# MSP430F5529 register map
Vendor: msp430gen; File version: v0.4.0-10-gd4db4bc
Registers are 8-bit, read-write, reset 0x0 unless marked. A register's access mark holds for its fields unless they carry their own. Offsets are from the block's base; [hi:lo] are bit positions; {n}, {i} and the like mark numbered series.

## USCI_A1_UART_MODE
Base 0x00000600
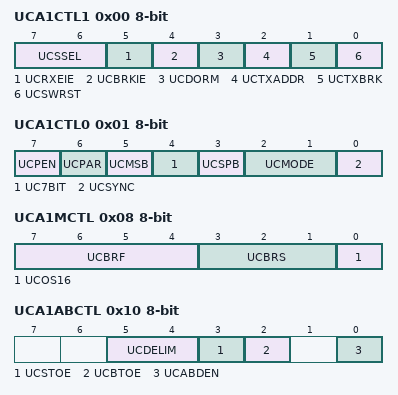
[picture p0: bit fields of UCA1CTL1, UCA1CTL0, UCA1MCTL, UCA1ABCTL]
0x00 UCA1CTL1 — USCI A1 Control Register 1
  [7:6] UCSSEL — USCI 0 Clock Source Select 1
    {v}=USCI 0 Clock Source: {v} (v=0..3)
  [5] UCRXEIE — RX Error interrupt enable
  [4] UCBRKIE — Break interrupt enable
  [3] UCDORM — Dormant (Sleep) Mode
  [2] UCTXADDR — Send next Data as Address
  [1] UCTXBRK — Send next Data as Break
  [0] UCSWRST — USCI Software Reset
0x01 UCA1CTL0 — USCI A1 Control Register 0
  [7] UCPEN — Async. Mode: Parity enable
  [6] UCPAR — Async. Mode: Parity 0:odd / 1:even
  [5] UCMSB — Async. Mode: MSB first 0:LSB / 1:MSB
  [4] UC7BIT — Async. Mode: Data Bits 0:8-bits / 1:7-bits
  [3] UCSPB — Async. Mode: Stop Bits 0:one / 1: two
  [2:1] UCMODE — Async. Mode: USCI Mode 1
    {v}=Sync. Mode: USCI Mode: {v} (v=0..3)
  [0] UCSYNC — Sync-Mode 0:UART-Mode / 1:SPI-Mode
0x06 UCA1BR0 — USCI A1 Baud Rate 0
  [7:0] UCA1BR0 — USCI A1 Baud Rate 0 register
0x07 UCA1BR1 — USCI A1 Baud Rate 1
  [7:0] UCA1BR1 — USCI A1 Baud Rate 1 register
0x08 UCA1MCTL — USCI A1 Modulation Control
  [7:4] UCBRF — USCI First Stage Modulation Select 3
    {v}=USCI First Stage Modulation: {v} (v=0..9); 10=USCI First Stage Modulation: A; 11=USCI First Stage Modulation: B; 12=USCI First Stage Modulation: C; 13=USCI First Stage Modulation: D; 14=USCI First Stage Modulation: E; 15=USCI First Stage Modulation: F
  [3:1] UCBRS — USCI Second Stage Modulation Select 2
    {v}=USCI Second Stage Modulation: {v} (v=0..7)
  [0] UCOS16 — USCI 16-times Oversampling enable
0x0A UCA1STAT — USCI A1 Status Register
  [7] UCLISTEN — USCI Listen mode
  [6] UCFE — USCI Frame Error Flag
  [5] UCOE — USCI Overrun Error Flag
  [4] UCPE — USCI Parity Error Flag
  [3] UCBRK — USCI Break received
  [2] UCRXERR — USCI RX Error Flag
  [1] UCADDR — USCI Address received Flag
  [1] UCIDLE — Idle line detected
  [0] UCBUSY — USCI Busy Flag
0x0C UCA1RXBUF — USCI A1 Receive Buffer
  [7:0] UCA1RXBUF — USCI A1 Receive Buffer register
0x0E UCA1TXBUF — USCI A1 Transmit Buffer
  [7:0] UCA1TXBUF — USCI A1 Transmit Buffer register
0x10 UCA1ABCTL — USCI A1 LIN Control
  [5:4] UCDELIM — Break Sync Delimiter 0
  [3] UCSTOE — Sync-Field Timeout error
  [2] UCBTOE — Break Timeout error
  [0] UCABDEN — Auto Baud Rate detect enable
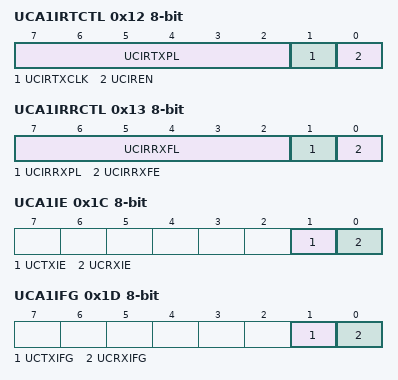
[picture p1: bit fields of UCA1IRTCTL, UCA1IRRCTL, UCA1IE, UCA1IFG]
0x12 UCA1IRTCTL — USCI A1 IrDA Transmit Control
  [7:2] UCIRTXPL — IRDA Transmit Pulse Length 0
  [1] UCIRTXCLK — IRDA Transmit Pulse Clock Select
  [0] UCIREN — IRDA Encoder/Decoder enable
0x13 UCA1IRRCTL — USCI A1 IrDA Receive Control
  [7:2] UCIRRXFL — IRDA Receive Filter Length 0
  [1] UCIRRXPL — IRDA Receive Input Polarity
  [0] UCIRRXFE — IRDA Receive Filter enable
0x1C UCA1IE — USCI A1 Interrupt Enable Register
  [1] UCTXIE — USCI Transmit Interrupt Enable
  [0] UCRXIE — USCI Receive Interrupt Enable
0x1D UCA1IFG — USCI A1 Interrupt Flags Register
  [1] UCTXIFG — USCI Transmit Interrupt Flag
  [0] UCRXIFG — USCI Receive Interrupt Flag
0x1E UCA1IV 16-bit — USCI A1 Interrupt Vector Register

## USCI_A1_SPI_MODE
Base 0x00000600
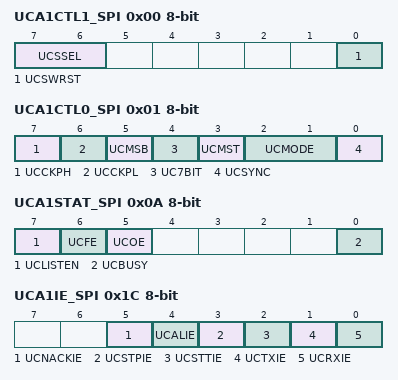
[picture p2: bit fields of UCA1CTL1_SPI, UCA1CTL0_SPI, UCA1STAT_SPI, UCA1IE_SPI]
0x00 UCA1CTL1_SPI — USCI A1 Control Register 1
  [7:6] UCSSEL — USCI 1 Clock Source Select 1
    {v}=USCI 0 Clock Source: {v} (v=0..3)
  [0] UCSWRST — USCI Software Reset
0x01 UCA1CTL0_SPI — USCI A1 Control Register 0
  [7] UCCKPH — Sync. Mode: Clock Phase
  [6] UCCKPL — Sync. Mode: Clock Polarity
  [5] UCMSB — Sync. Mode: MSB first 0:LSB / 1:MSB
  [4] UC7BIT — Sync. Mode: Data Bits 0:8-bits / 1:7-bits
  [3] UCMST — Sync. Mode: Master Select
  [2:1] UCMODE — Sync. Mode: USCI Mode 1
    {v}=Sync. Mode: USCI Mode: {v} (v=0..3)
  [0] UCSYNC — Sync-Mode 0:UART-Mode / 1:SPI-Mode
0x06 UCA1BR0_SPI — USCI A1 Baud Rate 0
0x07 UCA1BR1_SPI — USCI A1 Baud Rate 1
0x08 UCA1MCTL_SPI — USCI A1 Modulation Control
0x0A UCA1STAT_SPI — USCI A1 Status Register
  [7] UCLISTEN — USCI Listen mode
  [6] UCFE — USCI Frame Error Flag
  [5] UCOE — USCI Overrun Error Flag
  [0] UCBUSY — USCI Busy Flag
0x0C UCA1RXBUF_SPI — USCI A1 Receive Buffer
0x0E UCA1TXBUF_SPI — USCI A1 Transmit Buffer
0x1C UCA1IE_SPI — USCI A1 Interrupt Enable Register
  [5] UCNACKIE — NACK Condition interrupt enable
  [4] UCALIE — Arbitration Lost interrupt enable
  [3] UCSTPIE — STOP Condition interrupt enable
  [2] UCSTTIE — START Condition interrupt enable
  [1] UCTXIE — USCI Transmit Interrupt Enable
  [0] UCRXIE — USCI Receive Interrupt Enable
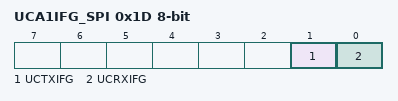
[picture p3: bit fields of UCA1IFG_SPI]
0x1D UCA1IFG_SPI — USCI A1 Interrupt Flags Register
  [1] UCTXIFG — USCI Transmit Interrupt Flag
  [0] UCRXIFG — USCI Receive Interrupt Flag
0x1E UCA1IV_SPI 16-bit — USCI A1 Interrupt Vector Register
